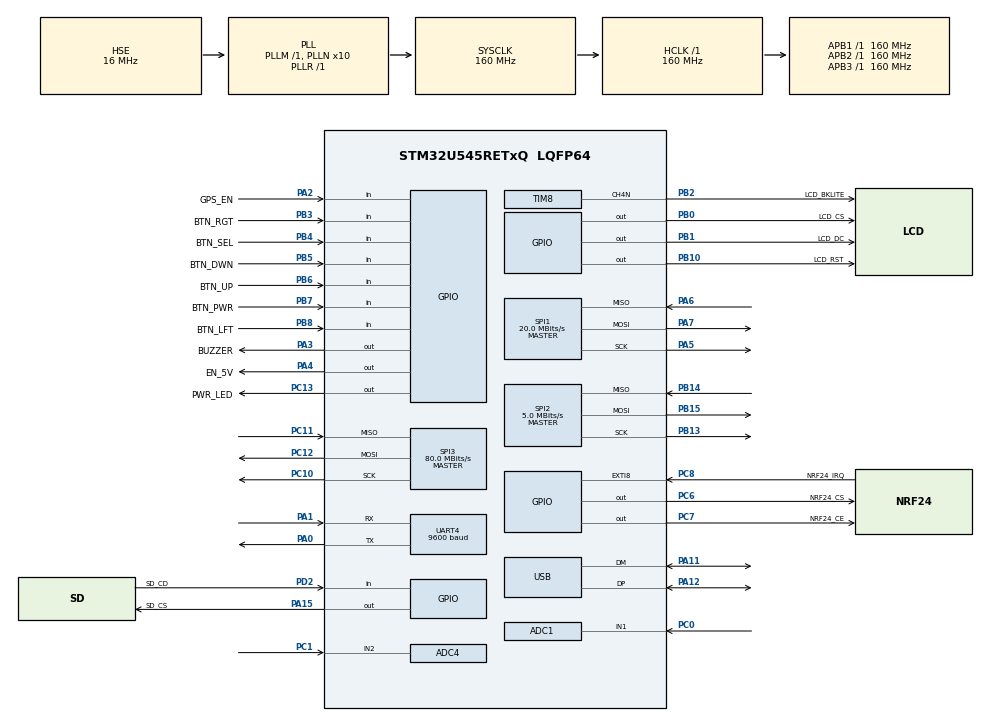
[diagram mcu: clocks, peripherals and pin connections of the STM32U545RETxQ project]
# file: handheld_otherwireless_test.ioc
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ADC1.Channel-6\#ChannelRegularConversion=ADC_CHANNEL_1
ADC1.ClockPrescaler=ADC_CLOCK_ASYNC_DIV4
ADC1.EnableAnalogWatchDog1=false
ADC1.MonitoredBy-6\#ChannelRegularConversion=__NULL
ADC1.NbrOfConversionFlag=1
ADC1.OffsetNumber-6\#ChannelRegularConversion=ADC_OFFSET_NONE
ADC1.Rank-6\#ChannelRegularConversion=1
ADC1.SamplingTime-6\#ChannelRegularConversion=ADC_SAMPLETIME_20CYCLES
ADC1.TriggerFrequencyMode=ADC_TRIGGER_FREQ_HIGH
ADC1.master=1
ADC4.Channel-0\#ChannelRegularConversion=ADC_CHANNEL_2
ADC4.ClockPrescaler=ADC_CLOCK_ASYNC_DIV4
ADC4.NbrOfConversionFlag=1
ADC4.OffsetNumber-0\#ChannelRegularConversion=ADC_OFFSET_NONE
ADC4.Rank-0\#ChannelRegularConversion=1
ADC4.RankArg-0\#ChannelRegularConversion=ADC4_REGULAR_RANK_1
ADC4.SamplingTime-0\#ChannelRegularConversion=ADC4_SAMPLINGTIME_COMMON_1
ADC4.SelectedChannel=ADC_CHANNEL_2
CORTEX_M33_NS.userName=CORTEX_M33
GPDMA1.DATAHANDLING_GPDMACH0=NONE
GPDMA1.DESTBURSTLENGTH_GPDMACH0=1
GPDMA1.DESTDATAWIDTH_GPDMACH0=DMA_DEST_DATAWIDTH_HALFWORD
GPDMA1.DIRECTION_GPDMACH0=DMA_MEMORY_TO_PERIPH
GPDMA1.IPHANDLE_GPDMACH0-SIMPLEREQUEST_GPDMACH0=__NULL
GPDMA1.PRIORITY_GPDMACH0=DMA_LOW_PRIORITY_LOW_WEIGHT
GPDMA1.REQUEST_GPDMACH0=GPDMA1_REQUEST_SPI1_TX
GPDMA1.SRCBURSTLENGTH_GPDMACH0=1
GPDMA1.SRCDATAWIDTH_GPDMACH0=DMA_SRC_DATAWIDTH_HALFWORD
GPDMA1.SRCINC_GPDMACH0=DMA_SINC_INCREMENTED
GPDMA1.TRIGGERPOLARITY_GPDMACH0=DMA_TRIG_POLARITY_MASKED
Mcu.Family=STM32U5
Mcu.Name=STM32U545RETxQ
Mcu.Package=LQFP64
NVIC.ADC1_IRQn=true\:0\:0\:false\:false\:true\:true\:true\:true
NVIC.EXTI8_IRQn=true\:0\:0\:false\:false\:true\:true\:true\:true
NVIC.GPDMA1_Channel0_IRQn=true\:0\:0\:false\:false\:true\:false\:true\:true
NVIC.PriorityGroup=NVIC_PRIORITYGROUP_4
NVIC.SPI1_IRQn=true\:0\:0\:false\:false\:true\:false\:true\:true
NVIC.TIM6_IRQn=true\:0\:0\:false\:false\:true\:true\:true\:true
NVIC.UART4_IRQn=true\:0\:0\:false\:false\:true\:true\:true\:true
PA0.Mode=Asynchronous
PA0.Signal=UART4_TX
PA1.Mode=Asynchronous
PA1.Signal=UART4_RX
PA11.Mode=Host
PA11.Signal=USB_DM
PA12.Mode=Host
PA12.Signal=USB_DP
PA13\ (JTMS/SWDIO).Mode=Serial_Wire
PA13\ (JTMS/SWDIO).Signal=DEBUG_JTMS-SWDIO
PA14\ (JTCK/SWCLK).Mode=Serial_Wire
PA14\ (JTCK/SWCLK).Signal=DEBUG_JTCK-SWCLK
PA15\ (JTDI).GPIO_Label=SD_CS
PA15\ (JTDI).Signal=GPIO_Output
PA2.GPIO_Label=GPS_EN
PA2.Signal=GPIO_Input
PA3.GPIO_Label=BUZZER
PA3.Signal=GPIO_Output
PA4.GPIO_Label=EN_5V
PA4.Signal=GPIO_Output
PA5.Mode=Full_Duplex_Master
PA5.Signal=SPI1_SCK
PA6.Mode=Full_Duplex_Master
PA6.Signal=SPI1_MISO
PA7.Mode=Full_Duplex_Master
PA7.Signal=SPI1_MOSI
PB0.GPIO_Label=LCD_CS
PB0.Signal=GPIO_Output
PB1.GPIO_Label=LCD_DC
PB1.Signal=GPIO_Output
PB10.GPIO_Label=LCD_RST
PB10.Signal=GPIO_Output
PB13.Mode=Full_Duplex_Master
PB13.Signal=SPI2_SCK
PB14.Mode=Full_Duplex_Master
PB14.Signal=SPI2_MISO
PB15.Mode=Full_Duplex_Master
PB15.Signal=SPI2_MOSI
PB2.GPIO_Label=LCD_BKLITE
PB2.Mode=PWM Generation4 CH4N
PB2.Signal=TIM8_CH4N
PB3\ (JTDO/TRACESWO).GPIO_Label=BTN_RGT
PB3\ (JTDO/TRACESWO).Signal=GPIO_Input
PB4\ (NJTRST).GPIO_Label=BTN_SEL
PB4\ (NJTRST).Signal=GPIO_Input
PB5.GPIO_Label=BTN_DWN
PB5.Signal=GPIO_Input
PB6.GPIO_Label=BTN_UP
PB6.Signal=GPIO_Input
PB7.GPIO_Label=BTN_PWR
PB7.Signal=GPIO_Input
PB8.GPIO_Label=BTN_LFT
PB8.Signal=GPIO_Input
PC0.Mode=IN1-Single-Ended
PC0.Signal=ADC1_IN1
PC1.Mode=IN2
PC1.Signal=ADC4_IN2
PC10.Mode=Full_Duplex_Master
PC10.Signal=SPI3_SCK
PC11.Mode=Full_Duplex_Master
PC11.Signal=SPI3_MISO
PC12.Mode=Full_Duplex_Master
PC12.Signal=SPI3_MOSI
PC13.GPIO_Label=PWR_LED
PC13.Signal=GPIO_Output
PC6.GPIO_Label=NRF24_CS
PC6.PinState=GPIO_PIN_SET
PC6.Signal=GPIO_Output
PC7.GPIO_Label=NRF24_CE
PC7.Signal=GPIO_Output
PC8.GPIO_Label=NRF24_IRQ
PC8.GPIO_ModeDefaultEXTI=GPIO_MODE_IT_FALLING
PC8.Signal=GPXTI8
PD2.GPIO_Label=SD_CD
PD2.Signal=GPIO_Input
PH0-OSC_IN\ (PH0).Mode=HSE-External-Oscillator
PH0-OSC_IN\ (PH0).Signal=RCC_OSC_IN
PH1-OSC_OUT\ (PH1).Mode=HSE-External-Oscillator
PH1-OSC_OUT\ (PH1).Signal=RCC_OSC_OUT
ProjectManager.HeapSize=0x200
ProjectManager.StackSize=0x400
ProjectManager.TargetToolchain=STM32CubeIDE
RCC.ADCCLockSelection=RCC_ADCDACCLKSOURCE_SYSCLK
RCC.ADCFreq_Value=160000000
RCC.AHBFreq_Value=160000000
RCC.APB1Freq_Value=160000000
RCC.APB1TimFreq_Value=160000000
RCC.APB2Freq_Value=160000000
RCC.APB2TimFreq_Value=160000000
RCC.APB3Freq_Value=160000000
RCC.CK48CLockSelection=RCC_CLK48CLKSOURCE_PLL2
RCC.CortexFreq_Value=160000000
RCC.DACCLockSelectionVirtual=RCC_DAC1CLKSOURCE_LSI
RCC.DACCLockSelectionVirtualString=RCC_DAC1CLKSOURCE_LSI
RCC.EPOD_VALUE=16000000
RCC.HCLKFreq_Value=160000000
RCC.HSE_VALUE=16000000
RCC.HSI48_VALUE=48000000
RCC.HSI_VALUE=16000000
RCC.LSE_VALUE=32768
RCC.LSIDIV_VALUE=32000
RCC.MSI_VALUE=4000000
RCC.PLL1Q=4
RCC.PLL1R=1
RCC.PLL2N=12
RCC.PLL2Q=4
RCC.PLL2Source=RCC_PLLSOURCE_HSE
RCC.PLLN=10
RCC.PLLSourceVirtual=RCC_PLLSOURCE_HSE
RCC.SYSCLKFreq_VALUE=160000000
RCC.SYSCLKSource=RCC_SYSCLKSOURCE_PLLCLK
RCC.USBFreq_Value=48000000
RCC.VCOOutputFreq_Value=160000000
SPI1.BaudRatePrescaler=SPI_BAUDRATEPRESCALER_8
SPI1.CalculateBaudRate=20.0 MBits/s
SPI1.DataSize=SPI_DATASIZE_8BIT
SPI1.Direction=SPI_DIRECTION_2LINES
SPI1.Mode=SPI_MODE_MASTER
SPI1.VirtualType=VM_MASTER
SPI2.BaudRatePrescaler=SPI_BAUDRATEPRESCALER_32
SPI2.CalculateBaudRate=5.0 MBits/s
SPI2.DataSize=SPI_DATASIZE_8BIT
SPI2.Direction=SPI_DIRECTION_2LINES
SPI2.Mode=SPI_MODE_MASTER
SPI2.VirtualType=VM_MASTER
SPI3.BaudRatePrescaler=SPI_BAUDRATEPRESCALER_2
SPI3.CalculateBaudRate=80.0 MBits/s
SPI3.Direction=SPI_DIRECTION_2LINES
SPI3.Mode=SPI_MODE_MASTER
SPI3.VirtualType=VM_MASTER
STMicroelectronics.X-CUBE-TOUCHGFX.4.23.2.tgfx_address1=0x20000000
STMicroelectronics.X-CUBE-TOUCHGFX.4.23.2.tgfx_custom_height=240
STMicroelectronics.X-CUBE-TOUCHGFX.4.23.2.tgfx_custom_width=320
STMicroelectronics.X-CUBE-TOUCHGFX.4.23.2.tgfx_location=Allocate
STMicroelectronics.X-CUBE-TOUCHGFX.4.23.2_IsPackSelfContextualization=true
TIM6.AutoReloadPreload=TIM_AUTORELOAD_PRELOAD_DISABLE
TIM6.PeriodNoDither=333
TIM6.Prescaler=16000
TIM6.TIM_MasterOutputTrigger=TIM_TRGO_RESET
TIM8.AutoReloadPreload=TIM_AUTORELOAD_PRELOAD_ENABLE
TIM8.Channel-PWM\ Generation4\ CH4N=TIM_CHANNEL_4
TIM8.OCNIdleState_4=TIM_OCNIDLESTATE_RESET
TIM8.PeriodNoDither=1600
TIM8.PulseNoDither_4=800
UART4.BaudRate=9600
VP_CRC_VS_CRC.Mode=CRC_Activate
VP_GPDMA1_VS_GPDMACH0.Mode=SIMPLEREQUEST_GPDMACH0
VP_LPBAMQUEUE_VS_QUEUE.Mode=QUEUEMODE
VP_LPBAM_VS_SIG1.Mode=SmartRun
VP_LPBAM_VS_SIG4.Mode=LPDMA1
VP_MEMORYMAP_VS_MEMORYMAP.Mode=CurAppReg
VP_PWR_VS_SECSignals.Mode=Security/Privilege
VP_PWR_Vdda.Mode=isolationVdda
VP_TIM6_VS_ClockSourceINT.Mode=Enable_Timer
board=custom

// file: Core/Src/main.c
/* USER CODE BEGIN Header */
/**
  ******************************************************************************
  * @file           : main.c
  * @brief          : Main program body
  ******************************************************************************
  * @attention
  *
  * Copyright (c) 2024 STMicroelectronics.
  * All rights reserved.
  *
  * This software is licensed under terms that can be found in the LICENSE file
  * in the root directory of this software component.
  * If no LICENSE file comes with this software, it is provided AS-IS.
  *
  ******************************************************************************
  */
/* USER CODE END Header */
#include "main.h"
#include "adc.h"
#include "crc.h"
#include "gpdma.h"
#include "memorymap.h"
#include "spi.h"
#include "tim.h"
#include "usart.h"
#include "usb_drd_fs.h"
#include "gpio.h"

/* USER CODE BEGIN Includes */
#include "nrf24l01p.h"
/* USER CODE END Includes */

void SystemClock_Config(void);

int main(void)
{

  /* MCU Configuration--------------------------------------------------------*/

  /* Reset of all peripherals, Initializes the Flash interface and the Systick. */
  HAL_Init();

  /* Configure the system clock */
  SystemClock_Config();

  /* Initialize all configured peripherals */
  MX_GPIO_Init();
  MX_GPDMA1_Init();
  MX_SPI2_Init();
  MX_SPI3_Init();
  MX_USB_DRD_FS_HCD_Init();
  MX_ADC1_Init();
  MX_ADC4_Init();
  MX_TIM8_Init();
  MX_SPI1_Init();
  MX_CRC_Init();
  MX_UART4_Init();
  MX_TIM6_Init();
  /* USER CODE BEGIN 2 */

  HAL_GPIO_WritePin(PWR_LED_GPIO_Port, PWR_LED_Pin, GPIO_PIN_SET);
  uint8_t tx_data[NRF24L01P_PAYLOAD_LENGTH] = {0, 1, 2, 3, 4, 5, 6, 7};
  nrf24l01p_tx_init(2500, _1Mbps);

  /* USER CODE END 2 */

  /* Infinite loop */
  /* USER CODE BEGIN WHILE */
  while (1)
  {
	  for(int i= 0; i < 8; i++)
		  tx_data[i]++;

	  // transmit
	  nrf24l01p_tx_transmit(tx_data);

	  if (!HAL_GPIO_ReadPin(NRF24_IRQ_GPIO_Port, NRF24_IRQ_Pin)) {
		  nrf24l01p_tx_irq();
	  }
	  HAL_Delay(100);
    /* USER CODE END WHILE */

  }
}

void SystemClock_Config(void)
{
  RCC_OscInitTypeDef RCC_OscInitStruct = {0};
  RCC_ClkInitTypeDef RCC_ClkInitStruct = {0};

  /** Configure the main internal regulator output voltage
  */
  if (HAL_PWREx_ControlVoltageScaling(PWR_REGULATOR_VOLTAGE_SCALE1) != HAL_OK)
  {
    Error_Handler();
  }

  /** Initializes the CPU, AHB and APB buses clocks
  */
  RCC_OscInitStruct.OscillatorType = RCC_OSCILLATORTYPE_HSE;
  RCC_OscInitStruct.HSEState = RCC_HSE_ON;
  RCC_OscInitStruct.PLL.PLLState = RCC_PLL_ON;
  RCC_OscInitStruct.PLL.PLLSource = RCC_PLLSOURCE_HSE;
  RCC_OscInitStruct.PLL.PLLMBOOST = RCC_PLLMBOOST_DIV1;
  RCC_OscInitStruct.PLL.PLLM = 1;
  RCC_OscInitStruct.PLL.PLLN = 10;
  RCC_OscInitStruct.PLL.PLLP = 2;
  RCC_OscInitStruct.PLL.PLLQ = 4;
  RCC_OscInitStruct.PLL.PLLR = 1;
  RCC_OscInitStruct.PLL.PLLRGE = RCC_PLLVCIRANGE_1;
  RCC_OscInitStruct.PLL.PLLFRACN = 0;
  if (HAL_RCC_OscConfig(&RCC_OscInitStruct) != HAL_OK)
  {
    Error_Handler();
  }

  /** Initializes the CPU, AHB and APB buses clocks
  */
  RCC_ClkInitStruct.ClockType = RCC_CLOCKTYPE_HCLK|RCC_CLOCKTYPE_SYSCLK
                              |RCC_CLOCKTYPE_PCLK1|RCC_CLOCKTYPE_PCLK2
                              |RCC_CLOCKTYPE_PCLK3;
  RCC_ClkInitStruct.SYSCLKSource = RCC_SYSCLKSOURCE_PLLCLK;
  RCC_ClkInitStruct.AHBCLKDivider = RCC_SYSCLK_DIV1;
  RCC_ClkInitStruct.APB1CLKDivider = RCC_HCLK_DIV1;
  RCC_ClkInitStruct.APB2CLKDivider = RCC_HCLK_DIV1;
  RCC_ClkInitStruct.APB3CLKDivider = RCC_HCLK_DIV1;

  if (HAL_RCC_ClockConfig(&RCC_ClkInitStruct, FLASH_LATENCY_4) != HAL_OK)
  {
    Error_Handler();
  }
}

void Error_Handler(void)
{
  __disable_irq();
  while (1)
  {
  }
}
